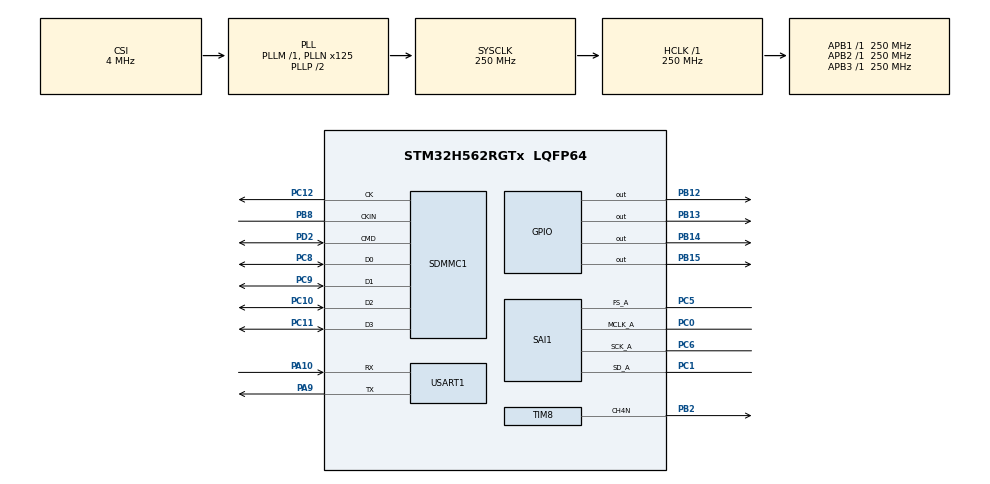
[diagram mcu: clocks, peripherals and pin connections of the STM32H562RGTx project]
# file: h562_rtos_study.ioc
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BOOTPATH.BootPathName=LEGACY
BOOTPATH.UserSelectedBootPath=LEGACY
CORTEX_M33_NS.userName=CORTEX_M33
FILEX.FILEX_APPLICATION_THREAD_STACK_SIZE=4096
FILEX.FX_APP_MEM_POOL_SIZE=8192
FILEX.FX_SD_INTERFACE=1
FILEX.useRTOS=1
GPDMA1.CIRCULARMODE_GPDMACH0=ENABLE
GPDMA1.CIRCULARMODE_GPDMACH1=ENABLE
GPDMA1.DESTBURSTLENGTH_GPDMACH1=4
GPDMA1.DESTDATAWIDTH_GPDMACH1=DMA_DEST_DATAWIDTH_HALFWORD
GPDMA1.DESTINC_GPDMACH0=DMA_DINC_INCREMENTED
GPDMA1.DIRECTION_GPDMACH0=DMA_PERIPH_TO_MEMORY
GPDMA1.DIRECTION_GPDMACH1=DMA_MEMORY_TO_PERIPH
GPDMA1.DMAHANDLE_GPDMACH0=hdmarx
GPDMA1.DMAHANDLE_GPDMACH1=hdmatx
GPDMA1.IPHANDLE_GPDMACH0-SIMPLEREQUEST_GPDMACH0=__NULL
GPDMA1.IPHANDLE_GPDMACH1-SIMPLEREQUEST_GPDMACH1=__NULL
GPDMA1.LINKALLOCATEDPORT_CIRCULAR_GPDMACH0=DMA_LINK_ALLOCATED_PORT1
GPDMA1.PRIORITY_LL_CIRCULAR_GPDMACH1=DMA_HIGH_PRIORITY
GPDMA1.REQUEST_GPDMACH0=GPDMA1_REQUEST_USART1_RX
GPDMA1.REQUEST_GPDMACH1=GPDMA1_REQUEST_SAI1_A
GPDMA1.SRCBURSTLENGTH_GPDMACH1=4
GPDMA1.SRCDATAWIDTH_GPDMACH1=DMA_SRC_DATAWIDTH_HALFWORD
GPDMA1.SRCINC_GPDMACH1=DMA_SINC_INCREMENTED
GPDMA1.TRANSFERALLOCATEDPORTDEST_GPDMACH0=DMA_DEST_ALLOCATED_PORT1
GPDMA1.TRANSFERALLOCATEDPORTSRC_GPDMACH0=DMA_SRC_ALLOCATED_PORT1
Mcu.Family=STM32H5
Mcu.Name=STM32H562RGTx
Mcu.Package=LQFP64
NVIC.GPDMA1_Channel0_IRQn=true\:0\:0\:false\:false\:true\:true\:false\:true\:true
NVIC.GPDMA1_Channel1_IRQn=true\:0\:0\:false\:false\:true\:true\:false\:true\:true
NVIC.PriorityGroup=NVIC_PRIORITYGROUP_4
NVIC.SAI1_IRQn=true\:0\:0\:false\:false\:true\:false\:true\:true\:true
NVIC.SDMMC1_IRQn=true\:0\:0\:false\:false\:true\:false\:true\:true\:true
NVIC.TIM17_IRQn=true\:15\:0\:false\:false\:true\:false\:false\:true\:true
NVIC.TimeBase=TIM17_IRQn
NVIC.TimeBaseIP=TIM17
NVIC.USART1_IRQn=true\:0\:0\:false\:false\:true\:false\:true\:true\:true
PA10.Mode=Asynchronous
PA10.Signal=USART1_RX
PA13(JTMS/SWDIO).Mode=Serial_Wire
PA13(JTMS/SWDIO).Signal=DEBUG_JTMS-SWDIO
PA14(JTCK/SWCLK).Mode=Serial_Wire
PA14(JTCK/SWCLK).Signal=DEBUG_JTCK-SWCLK
PA9.Mode=Asynchronous
PA9.Signal=USART1_TX
PB12.Signal=GPIO_Output
PB13.Signal=GPIO_Output
PB14.Signal=GPIO_Output
PB15.Signal=GPIO_Output
PB2.Mode=PWM Generation4 CH4N
PB2.Signal=TIM8_CH4N
PB8.GPIO_PuPd=GPIO_PULLUP
PB8.Mode=SD_4_bits_Wide_bus_auto_dir_voltage_converter
PB8.Signal=SDMMC1_CKIN
PC0.GPIO_PuPd=GPIO_PULLUP
PC0.GPIO_Speed=GPIO_SPEED_FREQ_VERY_HIGH
PC0.Mode=SAI_A_MasterWithClock
PC0.Signal=SAI1_MCLK_A
PC1.GPIO_PuPd=GPIO_PULLUP
PC1.GPIO_Speed=GPIO_SPEED_FREQ_VERY_HIGH
PC1.Mode=SAI_A_MasterWithClock
PC1.Signal=SAI1_SD_A
PC10.GPIO_PuPd=GPIO_PULLUP
PC10.Mode=SD_4_bits_Wide_bus_auto_dir_voltage_converter
PC10.Signal=SDMMC1_D2
PC11.Mode=SD_4_bits_Wide_bus_auto_dir_voltage_converter
PC11.Signal=SDMMC1_D3
PC12.GPIO_PuPd=GPIO_PULLUP
PC12.Mode=SD_4_bits_Wide_bus_auto_dir_voltage_converter
PC12.Signal=SDMMC1_CK
PC14-OSC32_IN(OSC32_IN).Mode=LSE-External-Oscillator
PC14-OSC32_IN(OSC32_IN).Signal=RCC_OSC32_IN
PC15-OSC32_OUT(OSC32_OUT).Mode=LSE-External-Oscillator
PC15-OSC32_OUT(OSC32_OUT).Signal=RCC_OSC32_OUT
PC5.GPIO_PuPd=GPIO_PULLUP
PC5.GPIO_Speed=GPIO_SPEED_FREQ_VERY_HIGH
PC5.Mode=SAI_A_MasterWithClock
PC5.Signal=SAI1_FS_A
PC6.GPIO_PuPd=GPIO_PULLUP
PC6.GPIO_Speed=GPIO_SPEED_FREQ_VERY_HIGH
PC6.Mode=SAI_A_MasterWithClock
PC6.Signal=SAI1_SCK_A
PC8.GPIO_PuPd=GPIO_PULLUP
PC8.Mode=SD_4_bits_Wide_bus_auto_dir_voltage_converter
PC8.Signal=SDMMC1_D0
PC9.GPIO_PuPd=GPIO_PULLUP
PC9.Mode=SD_4_bits_Wide_bus_auto_dir_voltage_converter
PC9.Signal=SDMMC1_D1
PD2.GPIO_PuPd=GPIO_PULLUP
PD2.Mode=SD_4_bits_Wide_bus_auto_dir_voltage_converter
PD2.Signal=SDMMC1_CMD
PH0-OSC_IN(PH0).Mode=HSE-External-Oscillator
PH0-OSC_IN(PH0).Signal=RCC_OSC_IN
PH1-OSC_OUT(PH1).Mode=HSE-External-Oscillator
PH1-OSC_OUT(PH1).Signal=RCC_OSC_OUT
ProjectManager.HeapSize=0x200
ProjectManager.StackSize=0x400
ProjectManager.TargetToolchain=CMake
RCC.ADCFreq_Value=250000000
RCC.AHBFreq_Value=250000000
RCC.APB1Freq_Value=250000000
RCC.APB1TimFreq_Value=250000000
RCC.APB2Freq_Value=250000000
RCC.APB2TimFreq_Value=250000000
RCC.APB3Freq_Value=250000000
RCC.CSI_VALUE=4000000
RCC.CortexFreq_Value=250000000
RCC.EPOD_VALUE=4000000
RCC.HCLKFreq_Value=250000000
RCC.HSE_VALUE=8000000
RCC.HSI48_VALUE=48000000
RCC.HSI_VALUE=64000000
RCC.LSIRC_VALUE=32000
RCC.PLL2FRACN=0
RCC.PLL2N=32
RCC.PLL2P=1
RCC.PLL3FRACN=0
RCC.PLL3M=10
RCC.PLL3N=134
RCC.PLL3P=38
RCC.PLL3Source=RCC_PLL3_SOURCE_HSI
RCC.PLLFRACN=0
RCC.PLLN=125
RCC.SAI1CLockSelection=RCC_SAI1CLKSOURCE_PLL3P
RCC.SYSCLKFreq_VALUE=250000000
RCC.SYSCLKSource=RCC_SYSCLKSOURCE_PLLCLK
RCC.USBFreq_Value=48000000
RCC.VCOOutputFreq_Value=500000000
SAI1.AudioFrequency-SAI_A_MasterWithClock=SAI_AUDIO_FREQUENCY_44K
SAI1.ErrorAudioFreq-SAI_A_MasterWithClock=-0.04 %
SAI1.FIFOThreshold-SAI_A_MasterWithClock=SAI_FIFOTHRESHOLD_HF
SAI1.InitProtocol-SAI_A_MasterWithClock=Enable
SAI1.Instance-SAI_A_MasterWithClock=SAI$Index_Block_A
SAI1.MckOutput=SAI_MCK_OUTPUT_ENABLE
SAI1.NoDivider-SAI_A_MasterWithClock=SAI_MASTERDIVIDER_ENABLE
SAI1.RealAudioFreq-SAI_A_MasterWithClock=44.078 KHz
SAI1.VirtualMode-SAI_A_MasterWithClock=VM_MASTER
SAI1.VirtualProtocol-SAI_A_BASIC=VM_BASIC_PROTOCOL
SDMMC1.ClockDiv=1
SDMMC1.ClockPowerSave=SDMMC_CLOCK_POWER_SAVE_ENABLE
SDMMC1.HardwareFlowControl=SDMMC_HARDWARE_FLOW_CONTROL_ENABLE
THREADX.TX_APP_CREATION=0
THREADX.TX_APP_GENERATE_INIT_CODE=true
THREADX.TX_MINIMUM_STACK=256
THREADX.TX_TIMER_TICKS_PER_SECOND=1000
TIM8.Channel-PWM\ Generation4\ CH4N=TIM_CHANNEL_4
TIM8.PeriodNoDither=1000
TIM8.Prescaler=249
TIM8.PulseNoDither_4=500
USART1.VirtualMode-Asynchronous=VM_ASYNC
VP_BOOTPATH_VS_BOOTPATH.Mode=BP_Activate
VP_CORTEX_M33_NS_VS_Hclk.Mode=Hclk_Mode
VP_FILEX_VS_FileOoSystemJjFileXJjCore.Mode=FileX_Core
VP_FILEX_VS_SDOointerface.Mode=SD_interface
VP_GPDMA1_VS_GPDMACH0.Mode=SIMPLEREQUEST_GPDMACH0
VP_GPDMA1_VS_GPDMACH1.Mode=SIMPLEREQUEST_GPDMACH1
VP_ICACHE_VS_ICACHE.Mode=DirectMappedCache
VP_MEMORYMAP_VS_MEMORYMAP.Mode=CurAppReg
VP_PWR_VS_LPOM.Mode=PowerOptimisation
VP_PWR_VS_SECSignals.Mode=Security/Privilege
VP_SAI1_VP_$IpInstance_SAIA_SAI_BASIC.Mode=SAI_A_BASIC
VP_SYS_VS_tim17.Mode=TIM17
VP_THREADX_VS_RTOSJjThreadXJjCoreJjDefault.Mode=Core_Default
board=custom

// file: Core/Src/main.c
/* USER CODE BEGIN Header */
/**
  ******************************************************************************
  * @file           : main.c
  * @brief          : Main program body
  ******************************************************************************
  * @attention
  *
  * Copyright (c) 2025 STMicroelectronics.
  * All rights reserved.
  *
  * This software is licensed under terms that can be found in the LICENSE file
  * in the root directory of this software component.
  * If no LICENSE file comes with this software, it is provided AS-IS.
  *
  ******************************************************************************
  */
/* USER CODE END Header */
#include "app_threadx.h"
#include "main.h"
#include "gpdma.h"
#include "icache.h"
#include "sai.h"
#include "sdmmc.h"
#include "tim.h"
#include "usart.h"
#include "gpio.h"

void SystemClock_Config(void);

int main(void)
{

  /* MCU Configuration--------------------------------------------------------*/

  /* Reset of all peripherals, Initializes the Flash interface and the Systick. */
  HAL_Init();

  /* Configure the system clock */
  SystemClock_Config();

  /* Initialize all configured peripherals */
  MX_GPIO_Init();
  MX_GPDMA1_Init();
  MX_ICACHE_Init();
  MX_USART1_UART_Init();
  MX_TIM8_Init();
  MX_SDMMC1_SD_Init();
  MX_SAI1_Init();
  /* USER CODE BEGIN 2 */
  tim_init();
  /* USER CODE END 2 */

  MX_ThreadX_Init();

  /* We should never get here as control is now taken by the scheduler */

  /* Infinite loop */
  while (1)
  {

  }
}

void SystemClock_Config(void)
{
  RCC_OscInitTypeDef RCC_OscInitStruct = {0};
  RCC_ClkInitTypeDef RCC_ClkInitStruct = {0};

  /** Configure the main internal regulator output voltage
  */
  __HAL_PWR_VOLTAGESCALING_CONFIG(PWR_REGULATOR_VOLTAGE_SCALE0);

  while(!__HAL_PWR_GET_FLAG(PWR_FLAG_VOSRDY)) {}

  /** Initializes the RCC Oscillators according to the specified parameters
  * in the RCC_OscInitTypeDef structure.
  */
  RCC_OscInitStruct.OscillatorType = RCC_OSCILLATORTYPE_HSI|RCC_OSCILLATORTYPE_CSI;
  RCC_OscInitStruct.HSIState = RCC_HSI_ON;
  RCC_OscInitStruct.HSIDiv = RCC_HSI_DIV2;
  RCC_OscInitStruct.HSICalibrationValue = RCC_HSICALIBRATION_DEFAULT;
  RCC_OscInitStruct.CSIState = RCC_CSI_ON;
  RCC_OscInitStruct.CSICalibrationValue = RCC_CSICALIBRATION_DEFAULT;
  RCC_OscInitStruct.PLL.PLLState = RCC_PLL_ON;
  RCC_OscInitStruct.PLL.PLLSource = RCC_PLL1_SOURCE_CSI;
  RCC_OscInitStruct.PLL.PLLM = 1;
  RCC_OscInitStruct.PLL.PLLN = 125;
  RCC_OscInitStruct.PLL.PLLP = 2;
  RCC_OscInitStruct.PLL.PLLQ = 2;
  RCC_OscInitStruct.PLL.PLLR = 2;
  RCC_OscInitStruct.PLL.PLLRGE = RCC_PLL1_VCIRANGE_2;
  RCC_OscInitStruct.PLL.PLLVCOSEL = RCC_PLL1_VCORANGE_WIDE;
  RCC_OscInitStruct.PLL.PLLFRACN = 0;
  if (HAL_RCC_OscConfig(&RCC_OscInitStruct) != HAL_OK)
  {
    Error_Handler();
  }

  /** Initializes the CPU, AHB and APB buses clocks
  */
  RCC_ClkInitStruct.ClockType = RCC_CLOCKTYPE_HCLK|RCC_CLOCKTYPE_SYSCLK
                              |RCC_CLOCKTYPE_PCLK1|RCC_CLOCKTYPE_PCLK2
                              |RCC_CLOCKTYPE_PCLK3;
  RCC_ClkInitStruct.SYSCLKSource = RCC_SYSCLKSOURCE_PLLCLK;
  RCC_ClkInitStruct.AHBCLKDivider = RCC_SYSCLK_DIV1;
  RCC_ClkInitStruct.APB1CLKDivider = RCC_HCLK_DIV1;
  RCC_ClkInitStruct.APB2CLKDivider = RCC_HCLK_DIV1;
  RCC_ClkInitStruct.APB3CLKDivider = RCC_HCLK_DIV1;

  if (HAL_RCC_ClockConfig(&RCC_ClkInitStruct, FLASH_LATENCY_5) != HAL_OK)
  {
    Error_Handler();
  }

  /** Configure the programming delay
  */
  __HAL_FLASH_SET_PROGRAM_DELAY(FLASH_PROGRAMMING_DELAY_2);
}

void HAL_TIM_PeriodElapsedCallback(TIM_HandleTypeDef *htim)
{
  if (htim->Instance == TIM17)
  {
    HAL_IncTick();
  }
}

void Error_Handler(void)
{
  __disable_irq();
  while (1)
  {
  }
}
